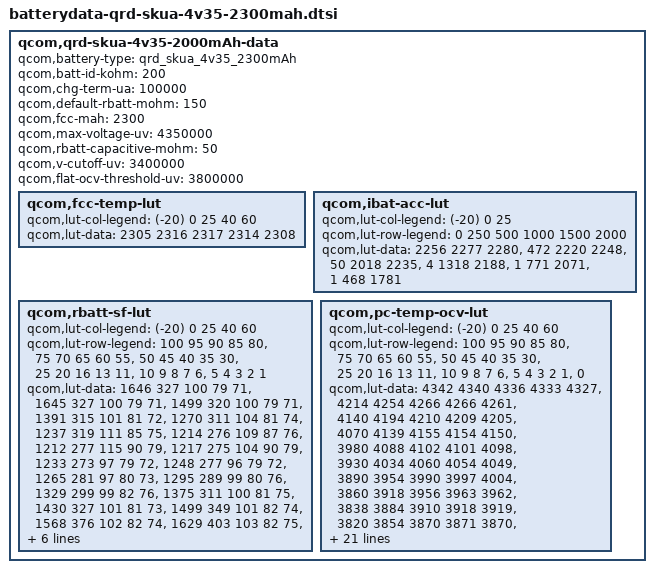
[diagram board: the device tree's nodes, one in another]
/* Copyright (c) 2014, The Linux Foundation. All rights reserved.
 *
 * This program is free software; you can redistribute it and/or modify
 * it under the terms of the GNU General Public License version 2 and
 * only version 2 as published by the Free Software Foundation.
 *
 * This program is distributed in the hope that it will be useful,
 * but WITHOUT ANY WARRANTY; without even the implied warranty of
 * MERCHANTABILITY or FITNESS FOR A PARTICULAR PURPOSE.  See the
 * GNU General Public License for more details.
 */

qcom,qrd-skua-4v35-2000mAh-data {
	qcom,battery-type = "qrd_skua_4v35_2300mAh";
	qcom,batt-id-kohm = <200>;
	qcom,chg-term-ua = <100000>;
	qcom,default-rbatt-mohm = <150>;
	qcom,fcc-mah = <2300>;
	qcom,max-voltage-uv = <4350000>;
	qcom,rbatt-capacitive-mohm = <50>;
	qcom,v-cutoff-uv = <3400000>;
	qcom,flat-ocv-threshold-uv = <3800000>;

	qcom,fcc-temp-lut {
		qcom,lut-col-legend = <(-20) 0 25 40 60>;
		qcom,lut-data = <2305 2316 2317 2314 2308>;
	};
  
	qcom,ibat-acc-lut {
		qcom,lut-col-legend = <(-20) 0 25>;
		qcom,lut-row-legend = <0 250 500 1000 1500 2000>;
		qcom,lut-data = <2256 2277 2280>,
                            <472 2220 2248>,
                            <50 2018 2235>,
                            <4 1318 2188>,
                            <1 771 2071>,
                            <1 468 1781>;
	};

	qcom,rbatt-sf-lut {
		qcom,lut-col-legend = <(-20) 0 25 40 60>;
		qcom,lut-row-legend = <100 95 90 85 80>,
					<75 70 65 60 55>,
					<50 45 40 35 30>,
					<25 20 16 13 11>,
					<10 9 8 7 6>,
					<5 4 3 2 1>;
		qcom,lut-data = <1646 327 100 79 71>, 
				<1645 327 100 79 71>, 
				<1499 320 100 79 71>, 
				<1391 315 101 81 72>, 
				<1270 311 104 81 74>, 
				<1237 319 111 85 75>, 
				<1214 276 109 87 76>, 
				<1212 277 115 90 79>, 
				<1217 275 104 90 79>, 
				<1233 273 97 79 72>, 
				<1248 277 96 79 72>, 
				<1265 281 97 80 73>, 
				<1295 289 99 80 76>, 
				<1329 299 99 82 76>, 
				<1375 311 100 81 75>, 
				<1430 327 101 81 73>, 
				<1499 349 101 82 74>, 
				<1568 376 102 82 74>, 
				<1629 403 103 82 75>, 
				<1653 420 103 83 75>, 
				<1634 426 104 83 76>, 
				<1679 443 105 85 78>, 
				<1807 462 109 87 79>, 
				<1988 485 112 88 81>, 
				<2218 509 115 89 81>, 
				<2511 535 113 87 78>, 
				<2918 569 115 87 79>, 
				<3496 619 119 89 80>, 
				<4469 690 126 92 83>, 
				<7151 1088 153 111 124>;
	};

	qcom,pc-temp-ocv-lut {
		qcom,lut-col-legend = <(-20) 0 25 40 60>;
		qcom,lut-row-legend = <100 95 90 85 80>,
					<75 70 65 60 55>,
					<50 45 40 35 30>,
					<25 20 16 13 11>,
					<10 9 8 7 6>,
					<5 4 3 2 1>,
					<0>;
		qcom,lut-data = <4342 4340 4336 4333 4327>, 
				<4214 4254 4266 4266 4261>, 
				<4140 4194 4210 4209 4205>, 
				<4070 4139 4155 4154 4150>, 
				<3980 4088 4102 4101 4098>, 
				<3930 4034 4060 4054 4049>, 
				<3890 3954 3990 3997 4004>, 
				<3860 3918 3956 3963 3962>, 
				<3838 3884 3910 3918 3919>, 
				<3820 3854 3870 3871 3870>, 
				<3804 3826 3841 3842 3840>, 
				<3788 3804 3818 3818 3817>, 
				<3774 3789 3798 3799 3798>, 
				<3758 3776 3782 3782 3781>, 
				<3743 3765 3768 3765 3760>, 
				<3724 3750 3754 3746 3734>, 
				<3702 3732 3736 3728 3714>, 
				<3679 3714 3716 3708 3694>, 
				<3658 3701 3697 3690 3676>, 
				<3640 3692 3688 3682 3670>, 
				<3631 3688 3686 3680 3668>, 
				<3619 3682 3684 3678 3667>, 
				<3604 3676 3682 3676 3663>, 
				<3588 3666 3676 3670 3657>, 
				<3566 3650 3666 3658 3642>, 
				<3540 3624 3637 3630 3610>, 
				<3506 3583 3591 3586 3562>, 
				<3459 3525 3530 3526 3502>, 
				<3390 3441 3444 3444 3416>, 
				<3286 3299 3308 3316 3285>, 
				<3000 3000 3000 3000 3000>;
	};
};

